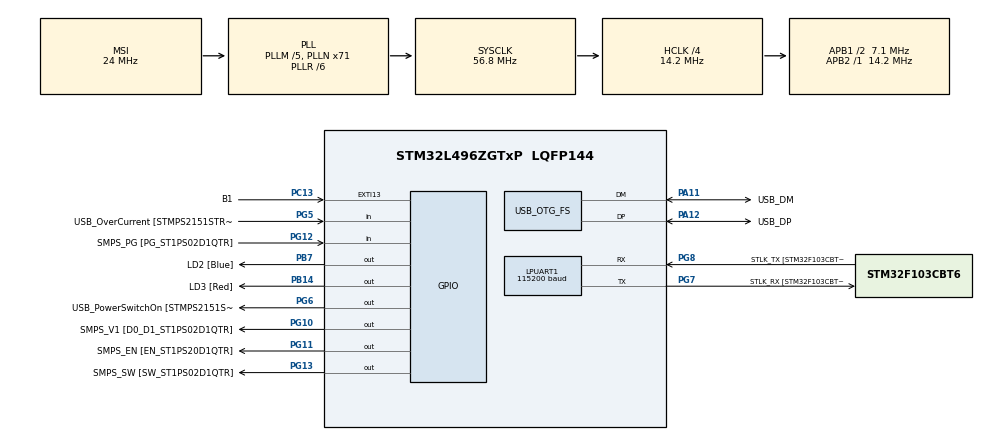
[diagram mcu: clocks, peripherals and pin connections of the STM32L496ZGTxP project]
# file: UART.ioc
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LPUART1.BaudRate=115200
LPUART1.WordLength=UART_WORDLENGTH_8B
Mcu.Family=STM32L4
Mcu.Name=STM32L496ZGTxP
Mcu.Package=LQFP144
NVIC.OTG_FS_IRQn=true\:0\:0\:false\:false\:true\:true\:true\:true
NVIC.PriorityGroup=NVIC_PRIORITYGROUP_4
PA10.GPIO_Label=USB_ID
PA10.Signal=USB_OTG_FS_ID
PA11.GPIO_Label=USB_DM
PA11.Mode=Host_Only
PA11.Signal=USB_OTG_FS_DM
PA12.GPIO_Label=USB_DP
PA12.Mode=Host_Only
PA12.Signal=USB_OTG_FS_DP
PA13\ (JTMS/SWDIO).GPIO_Label=TMS
PA13\ (JTMS/SWDIO).Mode=Trace_Asynchronous_SW
PA13\ (JTMS/SWDIO).Signal=SYS_JTMS-SWDIO
PA14\ (JTCK/SWCLK).GPIO_Label=TCK
PA14\ (JTCK/SWCLK).Mode=Trace_Asynchronous_SW
PA14\ (JTCK/SWCLK).Signal=SYS_JTCK-SWCLK
PA8.GPIO_Label=USB_SOF [TP1]
PA8.Signal=USB_OTG_FS_SOF
PA9.GPIO_Label=USB_VBUS
PA9.Signal=USB_OTG_FS_VBUS
PB14.GPIO_Label=LD3 [Red]
PB14.Signal=GPIO_Output
PB3\ (JTDO/TRACESWO).GPIO_Label=SWO
PB3\ (JTDO/TRACESWO).Mode=Trace_Asynchronous_SW
PB3\ (JTDO/TRACESWO).Signal=SYS_JTDO-SWO
PB7.GPIO_Label=LD2 [Blue]
PB7.Signal=GPIO_Output
PC13.GPIO_Label=B1
PC13.Signal=GPXTI13
PC14-OSC32_IN\ (PC14).Mode=LSE-External-Oscillator
PC14-OSC32_IN\ (PC14).Signal=RCC_OSC32_IN
PC15-OSC32_OUT\ (PC15).Mode=LSE-External-Oscillator
PC15-OSC32_OUT\ (PC15).Signal=RCC_OSC32_OUT
PG10.GPIO_Label=SMPS_V1 [D0_D1_ST1PS02D1QTR]
PG10.Signal=GPIO_Output
PG11.GPIO_Label=SMPS_EN [EN_ST1PS20D1QTR]
PG11.Signal=GPIO_Output
PG12.GPIO_Label=SMPS_PG [PG_ST1PS02D1QTR]
PG12.Signal=GPIO_Input
PG13.GPIO_Label=SMPS_SW [SW_ST1PS02D1QTR]
PG13.Signal=GPIO_Output
PG5.GPIO_Label=USB_OverCurrent [STMPS2151STR_FAULT]
PG5.Signal=GPIO_Input
PG6.GPIO_Label=USB_PowerSwitchOn [STMPS2151STR_EN]
PG6.Signal=GPIO_Output
PG7.GPIO_Label=STLK_RX [STM32F103CBT6_PA3]
PG7.Mode=Asynchronous
PG7.Signal=LPUART1_TX
PG8.GPIO_Label=STLK_TX [STM32F103CBT6_PA2]
PG8.Mode=Asynchronous
PG8.Signal=LPUART1_RX
PH0-OSC_IN\ (PH0).GPIO_Label=MCO
PH0-OSC_IN\ (PH0).Signal=RCC_OSC_IN
PH1-OSC_OUT\ (PH1).Signal=RCC_OSC_OUT
ProjectManager.HeapSize=0x200
ProjectManager.StackSize=0x400
ProjectManager.TargetToolchain=STM32CubeIDE
RCC.48MHZClocksFreq_Value=24000000
RCC.ADCFreq_Value=48000000
RCC.AHBCLKDivider=RCC_SYSCLK_DIV4
RCC.AHBFreq_Value=14200000
RCC.APB1CLKDivider=RCC_HCLK_DIV2
RCC.APB1Freq_Value=7100000
RCC.APB1TimFreq_Value=14200000
RCC.APB2Freq_Value=14200000
RCC.APB2TimFreq_Value=14200000
RCC.CortexFreq_Value=14200000
RCC.HCLKFreq_Value=14200000
RCC.HSE_VALUE=8000000
RCC.HSI48_VALUE=48000000
RCC.HSI_VALUE=16000000
RCC.MSIClockRange=RCC_MSIRANGE_9
RCC.MSI_VALUE=24000000
RCC.PLLM=5
RCC.PLLMUL=RCC_PLL_MUL9
RCC.PLLN=71
RCC.PLLR=RCC_PLLR_DIV6
RCC.PLLSAI1N=20
RCC.PRESCALERUSB=RCC_USBCLKSOURCE_PLL_DIV1_5
RCC.SYSCLKFreq_VALUE=56800000
RCC.SYSCLKSource=RCC_SYSCLKSOURCE_PLLCLK
RCC.SYSCLKSourceVirtual=RCC_SYSCLKSOURCE_PLLCLK
RCC.USBFreq_Value=48000000
RCC.VCOOutputFreq_Value=340800000
USB_HOST.BSP.number=1
USB_HOST.USBH_HandleTypeDef=hUsbHostFS
USB_HOST.VirtualModeFS=Audio
USB_HOST0.BSP.STBoard=false
USB_HOST0.BSP.api=UnknownBspDriver
USB_HOST0.BSP.instance=PG6
USB_HOST0.BSP.ip=GPIO
USB_HOST0.BSP.mode=Output
USB_HOST0.BSP.name=Drive_VBUS_FS
USB_HOST0.BSP.solution=PG6
USB_OTG_FS.VirtualMode=Host_Only
USB_OTG_FS.phy_itface=HCD_PHY_EMBEDDED
VP_USB_HOST_VS_USB_HOST_AUDIO_FS.Mode=AUDIO_FS
board=NUCLEO-L496ZG-P

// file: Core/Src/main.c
/* USER CODE BEGIN Header */
/**
  ******************************************************************************
  * @file           : main.c
  * @brief          : Main program body
  ******************************************************************************
  * @attention
  *
  * Copyright (c) 2022 STMicroelectronics.
  * All rights reserved.
  *
  * This software is licensed under terms that can be found in the LICENSE file
  * in the root directory of this software component.
  * If no LICENSE file comes with this software, it is provided AS-IS.
  *
  ******************************************************************************
  */
/* USER CODE END Header */
#include "main.h"
#include "usb_host.h"
#include<string.h>

#define  TRUE  	1
#define  FALSE 	0

UART_HandleTypeDef hlpuart1;

void SystemClock_Config(void);
static void MX_GPIO_Init(void);
static void MX_LPUART1_UART_Init(void);
void MX_USB_HOST_Process(void);
uint8_t convert_to_capital(uint8_t Data);

/* USER CODE BEGIN 0 */
char *user_data = "Applicaton is running\r\n";

uint8_t rcvd_Data;
uint32_t count = 0;
uint8_t data_buffer[100];
uint8_t reception_complete = FALSE;

/* USER CODE END 0 */

int main(void)
{

  HAL_Init();

  SystemClock_Config();

  MX_GPIO_Init();
  MX_LPUART1_UART_Init();
  MX_USB_HOST_Init();

  uint16_t len = strlen(user_data);
  HAL_UART_Transmit(&hlpuart1, (uint8_t *)user_data, len, HAL_MAX_DELAY);

  while(reception_complete != TRUE){
	  HAL_UART_Receive_IT(&hlpuart1, &rcvd_Data, 1);

  }

  while (1);

return 0;
}

void HAL_UART_RxCpltCallback(UART_HandleTypeDef *huart)
{

	if(rcvd_Data == '\r'){

		reception_complete = TRUE;
		data_buffer[count++] = '\r';
		HAL_UART_Transmit(&hlpuart1, data_buffer, count, HAL_MAX_DELAY);
	}else{
		data_buffer[count++] = rcvd_Data;
	}

}

uint8_t convert_to_capital(uint8_t Data){

	if(Data >= 'a' && Data <= 'z'){
		Data = Data - 32;
	}

	return Data;
}

void SystemClock_Config(void)
{
  RCC_OscInitTypeDef RCC_OscInitStruct = {0};
  RCC_ClkInitTypeDef RCC_ClkInitStruct = {0};

  /** Configure the main internal regulator output voltage
  */
  if (HAL_PWREx_ControlVoltageScaling(PWR_REGULATOR_VOLTAGE_SCALE1) != HAL_OK)
  {
    Error_Handler();
  }

  /** Configure LSE Drive Capability
  */
  HAL_PWR_EnableBkUpAccess();
  __HAL_RCC_LSEDRIVE_CONFIG(RCC_LSEDRIVE_LOW);

  /** Initializes the RCC Oscillators according to the specified parameters
  * in the RCC_OscInitTypeDef structure.
  */
  RCC_OscInitStruct.OscillatorType = RCC_OSCILLATORTYPE_LSE|RCC_OSCILLATORTYPE_MSI;
  RCC_OscInitStruct.LSEState = RCC_LSE_ON;
  RCC_OscInitStruct.MSIState = RCC_MSI_ON;
  RCC_OscInitStruct.MSICalibrationValue = 0;
  RCC_OscInitStruct.MSIClockRange = RCC_MSIRANGE_9;
  RCC_OscInitStruct.PLL.PLLState = RCC_PLL_ON;
  RCC_OscInitStruct.PLL.PLLSource = RCC_PLLSOURCE_MSI;
  RCC_OscInitStruct.PLL.PLLM = 5;
  RCC_OscInitStruct.PLL.PLLN = 71;
  RCC_OscInitStruct.PLL.PLLP = RCC_PLLP_DIV2;
  RCC_OscInitStruct.PLL.PLLQ = RCC_PLLQ_DIV2;
  RCC_OscInitStruct.PLL.PLLR = RCC_PLLR_DIV6;
  if (HAL_RCC_OscConfig(&RCC_OscInitStruct) != HAL_OK)
  {
    Error_Handler();
  }

  /** Initializes the CPU, AHB and APB buses clocks
  */
  RCC_ClkInitStruct.ClockType = RCC_CLOCKTYPE_HCLK|RCC_CLOCKTYPE_SYSCLK
                              |RCC_CLOCKTYPE_PCLK1|RCC_CLOCKTYPE_PCLK2;
  RCC_ClkInitStruct.SYSCLKSource = RCC_SYSCLKSOURCE_PLLCLK;
  RCC_ClkInitStruct.AHBCLKDivider = RCC_SYSCLK_DIV4;
  RCC_ClkInitStruct.APB1CLKDivider = RCC_HCLK_DIV2;
  RCC_ClkInitStruct.APB2CLKDivider = RCC_HCLK_DIV1;

  if (HAL_RCC_ClockConfig(&RCC_ClkInitStruct, FLASH_LATENCY_0) != HAL_OK)
  {
    Error_Handler();
  }

  /** Enable MSI Auto calibration
  */
  HAL_RCCEx_EnableMSIPLLMode();
}

static void MX_LPUART1_UART_Init(void)
{

  hlpuart1.Instance = LPUART1;
  hlpuart1.Init.BaudRate = 115200;
  hlpuart1.Init.WordLength = UART_WORDLENGTH_8B;
  hlpuart1.Init.StopBits = UART_STOPBITS_1;
  hlpuart1.Init.Parity = UART_PARITY_NONE;
  hlpuart1.Init.Mode = UART_MODE_TX_RX;
  hlpuart1.Init.HwFlowCtl = UART_HWCONTROL_NONE;
  hlpuart1.Init.OneBitSampling = UART_ONE_BIT_SAMPLE_DISABLE;
  hlpuart1.AdvancedInit.AdvFeatureInit = UART_ADVFEATURE_NO_INIT;
  if (HAL_UART_Init(&hlpuart1) != HAL_OK)
  {
    Error_Handler();
  }

}

static void MX_GPIO_Init(void)
{
  GPIO_InitTypeDef GPIO_InitStruct = {0};

  /* GPIO Ports Clock Enable */
  __HAL_RCC_GPIOC_CLK_ENABLE();
  __HAL_RCC_GPIOH_CLK_ENABLE();
  __HAL_RCC_GPIOB_CLK_ENABLE();
  __HAL_RCC_GPIOG_CLK_ENABLE();
  HAL_PWREx_EnableVddIO2();
  __HAL_RCC_GPIOA_CLK_ENABLE();

  /*Configure GPIO pin Output Level */
  HAL_GPIO_WritePin(GPIOB, LD3_Pin|LD2_Pin, GPIO_PIN_RESET);

  /*Configure GPIO pin Output Level */
  HAL_GPIO_WritePin(GPIOG, USB_PowerSwitchOn_Pin|SMPS_V1_Pin|SMPS_EN_Pin|SMPS_SW_Pin, GPIO_PIN_RESET);

  /*Configure GPIO pin : B1_Pin */
  GPIO_InitStruct.Pin = B1_Pin;
  GPIO_InitStruct.Mode = GPIO_MODE_IT_RISING;
  GPIO_InitStruct.Pull = GPIO_NOPULL;
  HAL_GPIO_Init(B1_GPIO_Port, &GPIO_InitStruct);

  /*Configure GPIO pins : LD3_Pin LD2_Pin */
  GPIO_InitStruct.Pin = LD3_Pin|LD2_Pin;
  GPIO_InitStruct.Mode = GPIO_MODE_OUTPUT_PP;
  GPIO_InitStruct.Pull = GPIO_NOPULL;
  GPIO_InitStruct.Speed = GPIO_SPEED_FREQ_LOW;
  HAL_GPIO_Init(GPIOB, &GPIO_InitStruct);

  /*Configure GPIO pins : USB_OverCurrent_Pin SMPS_PG_Pin */
  GPIO_InitStruct.Pin = USB_OverCurrent_Pin|SMPS_PG_Pin;
  GPIO_InitStruct.Mode = GPIO_MODE_INPUT;
  GPIO_InitStruct.Pull = GPIO_NOPULL;
  HAL_GPIO_Init(GPIOG, &GPIO_InitStruct);

  /*Configure GPIO pins : USB_PowerSwitchOn_Pin SMPS_V1_Pin SMPS_EN_Pin SMPS_SW_Pin */
  GPIO_InitStruct.Pin = USB_PowerSwitchOn_Pin|SMPS_V1_Pin|SMPS_EN_Pin|SMPS_SW_Pin;
  GPIO_InitStruct.Mode = GPIO_MODE_OUTPUT_PP;
  GPIO_InitStruct.Pull = GPIO_NOPULL;
  GPIO_InitStruct.Speed = GPIO_SPEED_FREQ_LOW;
  HAL_GPIO_Init(GPIOG, &GPIO_InitStruct);

}

void Error_Handler(void)
{
  __disable_irq();
  while (1)
  {
  }
}
